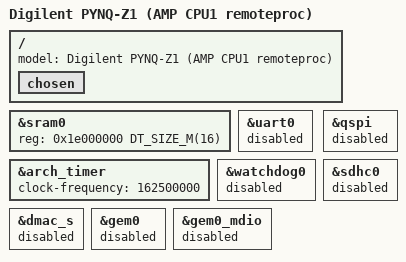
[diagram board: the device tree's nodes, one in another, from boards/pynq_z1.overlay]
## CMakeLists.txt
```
cmake_minimum_required(VERSION 3.20.0)

find_package(Zephyr REQUIRED HINTS $ENV{ZEPHYR_BASE})
project(pynq_z1_amp_cpu1)

target_sources(app PRIVATE src/main.c)
zephyr_linker_sources(SECTIONS resource_table.ld)
```

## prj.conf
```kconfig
# AMP CPU1 configuration: coexist with Linux on CPU0
CONFIG_USE_SWITCH=y
CONFIG_FPU=n
CONFIG_SMP=n
CONFIG_MP_MAX_NUM_CPUS=1
CONFIG_GIC_SAFE_CONFIG=y
CONFIG_NOCACHE_MEMORY=y
CONFIG_CACHE_MANAGEMENT=y

# OpenAMP / RPMsg (remote/device role paired with Linux zynq_remoteproc)
CONFIG_OPENAMP=y
CONFIG_OPENAMP_MASTER=n
CONFIG_OPENAMP_SLAVE=y
CONFIG_HEAP_MEM_POOL_SIZE=16384
CONFIG_MAIN_STACK_SIZE=4096

# Linux on CPU0 owns UART0 and Ethernet GEM0; log via remoteproc RSC_TRACE
CONFIG_SERIAL=n
CONFIG_CONSOLE=n
CONFIG_UART_CONSOLE=n
CONFIG_BOOT_BANNER=n
CONFIG_PRINTK=n
CONFIG_LOG=n
```

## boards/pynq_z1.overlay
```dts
/*
 * SPDX-License-Identifier: Apache-2.0
 *
 * Relocate Zephyr into the 16 MiB remoteproc carveout (0x1e000000) and disable
 * peripherals owned by Linux on CPU0 (UART0, GEM0).
 */

/ {
	model = "Digilent PYNQ-Z1 (AMP CPU1 remoteproc)";

	chosen {
		/delete-property/ zephyr,console;
		/delete-property/ zephyr,shell-uart;
	};
};

&sram0 {
	reg = <0x1e000000 DT_SIZE_M(16)>;
};

/* PYNQ Linux configures Cortex-A9 GTC_CTRL prescaler=1 (/2): 325 MHz / 2 = 162.5 MHz */
&arch_timer {
	clock-frequency = <162500000>;
};

&uart0 {
	status = "disabled";
};

&watchdog0 {
	status = "disabled";
};

&qspi {
	status = "disabled";
};

&sdhc0 {
	status = "disabled";
};

&dmac_s {
	status = "disabled";
};

&gem0 {
	status = "disabled";
};

&gem0_mdio {
	status = "disabled";
};
```

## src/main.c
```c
/*
 * SPDX-License-Identifier: Apache-2.0
 *
 * Zephyr AMP + OpenAMP/RPMsg firmware for Zynq-7000 CPU1 loaded by Linux
 * zynq_remoteproc.
 *  - Trace buffer: /sys/kernel/debug/remoteproc/remoteproc0/trace0
 *  - RPMsg echo endpoint: "rpmsg-raw" (/dev/rpmsg0 via Linux rpmsg_char)
 *  - Inter-processor kicks: GICv1 SGI #14 (Linux -> CPU1) and SGI #15 (CPU1 -> Linux)
 */

#include <zephyr/arch/cpu.h>
#include <zephyr/cache.h>
#include <zephyr/irq.h>
#include <zephyr/kernel.h>
#include <zephyr/linker/linker-defs.h>
#include <zephyr/linker/section_tags.h>
#include <zephyr/sys/barrier.h>
#include <zephyr/sys/sys_io.h>
#include <cmsis_core.h>
#include <openamp/open_amp.h>
#include <metal/io.h>
#include <metal/sys.h>
#include <stddef.h>
#include <stdint.h>
#include <stdio.h>
#include <stdlib.h>
#include <string.h>

#define AMP_TRACE_BUF_SIZE 2048U

/* Shared memory layout matching amp/openamp.dts */
#define SHM_REGION_ADDR 0x1F000000U
#define SHM_REGION_SIZE 0x00108000U
#define VRING0_ADDR     0x1F000000U
#define VRING1_ADDR     0x1F004000U
#define VRING_ALIGN     4096U
#define VRING_NUM       16U

/* Zynq-7000 GICv1 SGI registers (zynq_remoteproc uses SGIs 14 and 15) */
#define GICD_SGIR_ADDR   0xF8F01F00U
#define SGI_FROM_LINUX_0 14U
#define SGI_FROM_LINUX_1 15U
#define SGI_TO_LINUX     15U

/* PYNQ-Z1 base.bit AXI GPIO physical addresses (from base.hwh) */
#define AXI_SW_BASE      0x41200000U /* SW0-SW1 (2 bits) */
#define AXI_BTN_BASE     0x41210000U /* BTN0-BTN3 (4 bits) */
#define AXI_RGB_BASE     0x41240000U /* LD4-LD5 RGB (6 bits) */
#define AXI_LED_BASE     0x41250000U /* LD0-LD3 (4 bits) */
#define AXI_GPIO_DATA    0x00U
#define AXI_GPIO_TRI     0x04U

#define RPMSG_SVC_NAME "rpmsg-raw"

static char amp_trace_buf[AMP_TRACE_BUF_SIZE] __nocache;
static size_t amp_trace_pos;

void relocate_vector_table(void)
{
	uint32_t sctlr = __get_SCTLR();

	L1C_InvalidateICacheAll();
	L1C_InvalidateBTAC();
	L1C_InvalidateDCacheAll();
	/* Join Cortex-A9 SCU coherency (Linux already enabled SCU on CPU0) */
	__set_ACTLR(__get_ACTLR() | BIT(6) | BIT(0));

	sctlr &= ~SCTLR_V_Msk; /* Clear HIVECS so VBAR is active */
	__set_SCTLR(sctlr);
	__set_VBAR((uint32_t)_vector_start);
	barrier_dsync_fence_full();
	barrier_isync_fence_full();
}

struct amp_resource_table {
	uint32_t ver;
	uint32_t num;
	uint32_t reserved[2];
	uint32_t offset[2];
	struct fw_rsc_trace trace;
	struct fw_rsc_vdev rpmsg_vdev;
	struct fw_rsc_vdev_vring vring0;
	struct fw_rsc_vdev_vring vring1;
} __packed;

__attribute__((section(".resource_table"), used))
struct amp_resource_table rproc_resource_table = {
	.ver = 1U,
	.num = 2U,
	.reserved = { 0U, 0U },
	.offset = {
		offsetof(struct amp_resource_table, trace),
		offsetof(struct amp_resource_table, rpmsg_vdev),
	},
	.trace = {
		.type = RSC_TRACE,
		.da = (uint32_t)(uintptr_t)amp_trace_buf,
		.len = AMP_TRACE_BUF_SIZE,
		.reserved = 0U,
		.name = "zephyr_cpu1_trace",
	},
	.rpmsg_vdev = {
		.type = RSC_VDEV,
		.id = VIRTIO_ID_RPMSG,
		.notifyid = 0U,
		.dfeatures = (1U << VIRTIO_RPMSG_F_NS),
		.gfeatures = 0U,
		.config_len = 0U,
		.status = 0U,
		.num_of_vrings = 2U,
		.reserved = { 0U, 0U },
	},
	.vring0 = {
		.da = VRING0_ADDR,
		.align = VRING_ALIGN,
		.num = VRING_NUM,
		.notifyid = 0U,
		.reserved = 0U,
	},
	.vring1 = {
		.da = VRING1_ADDR,
		.align = VRING_ALIGN,
		.num = VRING_NUM,
		.notifyid = 1U,
		.reserved = 0U,
	},
};

static void trace_append(const char *msg)
{
	size_t len = strlen(msg);

	if (len >= AMP_TRACE_BUF_SIZE - 1U) {
		return;
	}

	if (amp_trace_pos + len >= AMP_TRACE_BUF_SIZE - 1U) {
		amp_trace_pos = 0U;
	}

	memcpy(&amp_trace_buf[amp_trace_pos], msg, len);
	amp_trace_pos += len;
	amp_trace_buf[amp_trace_pos] = '\0';
	barrier_dsync_fence_full();
}

static K_SEM_DEFINE(rpmsg_kick_sem, 0, 1);
static struct metal_io_region shm_io;
static struct metal_io_region rsc_io;
static metal_phys_addr_t shm_phys = SHM_REGION_ADDR;
static metal_phys_addr_t rsc_phys;
static struct rpmsg_virtio_device rvdev;
static struct rpmsg_endpoint raw_ept;
static uint32_t msg_count;
static uint32_t blink_period_ms;
static uint8_t blink_step;

static void axi_gpio_init_pl(void)
{
	/* Configure LD0-LD3 and RGB LD4-LD5 as outputs (TRI=0) */
	sys_write32(0x0U, AXI_LED_BASE + AXI_GPIO_TRI);
	sys_write32(0x0U, AXI_RGB_BASE + AXI_GPIO_TRI);
}

static void blink_timer_cb(struct k_timer *timer)
{
	static const uint8_t pattern[4] = { 0x1U, 0x2U, 0x4U, 0x8U };

	ARG_UNUSED(timer);
	sys_write32(pattern[blink_step & 0x3U], AXI_LED_BASE + AXI_GPIO_DATA);
	blink_step++;
}

static K_TIMER_DEFINE(pl_blink_timer, blink_timer_cb, NULL);

/* 1 kHz real-time jitter benchmark (325 MHz Cortex-A9 Global Timer) */
struct jitter_bench {
	struct k_sem done;
	uint32_t target_samples;
	uint32_t count;
	uint32_t prev_cyc;
	uint32_t min_cyc;
	uint32_t max_cyc;
	uint32_t max_err_cyc;
	uint64_t sum_cyc;
};

static struct jitter_bench jbench;

static void jitter_timer_cb(struct k_timer *timer)
{
	uint32_t now = k_cycle_get_32();

	if (jbench.count > 0U) {
		uint32_t dt = now - jbench.prev_cyc;
		uint32_t expected = CONFIG_SYS_CLOCK_HW_CYCLES_PER_SEC / 1000U;
		uint32_t err = (dt > expected) ? (dt - expected) : (expected - dt);

		if (dt < jbench.min_cyc) {
			jbench.min_cyc = dt;
		}
		if (dt > jbench.max_cyc) {
			jbench.max_cyc = dt;
		}
		if (err > jbench.max_err_cyc) {
			jbench.max_err_cyc = err;
		}
		jbench.sum_cyc += dt;
	}

	jbench.prev_cyc = now;
	jbench.count++;

	/* Toggle LD0 on every tick to prove live PL I/O inside the 1 kHz ISR */
	sys_write32(jbench.count & 0x1U, AXI_LED_BASE + AXI_GPIO_DATA);

	if (jbench.count > jbench.target_samples) {
		k_timer_stop(timer);
		k_sem_give(&jbench.done);
	}
}

static K_TIMER_DEFINE(jitter_timer, jitter_timer_cb, NULL);

/* Real-time 1 kHz failsafe supervisor (Linux heartbeat watchdog + PL BTN0 kill) */
enum ctrl_state {
	CTRL_DISARMED = 0,
	CTRL_ARMED = 1,
	CTRL_FAILSAFE = 2,
};

#define FAILSAFE_TIMEOUT_MS 500U
#define FAILSAFE_REBOOT_MS  5000U
#define SLCR_UNLOCK_REG     0xF8000008U
#define SLCR_PSS_RST_CTRL   0xF8000200U
#define RGB_BLUE_BOTH       0x09U /* LD4 blue (bit 0) + LD5 blue (bit 3) */
#define RGB_GREEN_BOTH      0x12U /* LD4 green (bit 1) + LD5 green (bit 4) */
#define RGB_RED_BOTH        0x24U /* LD4 red (bit 2) + LD5 red (bit 5) */

static volatile enum ctrl_state ctrl_mode = CTRL_DISARMED;
static volatile uint32_t last_cmd_ms;
static volatile uint32_t failsafe_enter_ms;
static volatile uint32_t ctrl_tick_count;
static volatile uint32_t failsafe_reason; /* 0=none, 1=timeout, 2=BTN0 kill */

static void zynq_ps_hardware_reset(void)
{
	/* Unlock Zynq-7000 SLCR and assert PSS_RST_CTRL (full PS reset) */
	sys_write32(0xDF0DU, SLCR_UNLOCK_REG);
	__DSB();
	sys_write32(0x1U, SLCR_PSS_RST_CTRL);
	__DSB();
	for (;;) {
		__WFE();
	}
}

static const char *ctrl_state_str(enum ctrl_state s)
{
	switch (s) {
	case CTRL_ARMED:
		return "ARMED";
	case CTRL_FAILSAFE:
		return "FAILSAFE";
	default:
		return "DISARMED";
	}
}

static void ctrl_timer_cb(struct k_timer *timer)
{
	ARG_UNUSED(timer);
	ctrl_tick_count++;

	if (ctrl_mode == CTRL_ARMED) {
		uint32_t btns = sys_read32(AXI_BTN_BASE + AXI_GPIO_DATA) & 0xFU;
		uint32_t now_ms = k_uptime_get_32();

		if ((btns & 0x1U) != 0U) {
			ctrl_mode = CTRL_FAILSAFE;
			failsafe_reason = 2U;
			sys_write32(0U, AXI_LED_BASE + AXI_GPIO_DATA);
			sys_write32(RGB_RED_BOTH, AXI_RGB_BASE + AXI_GPIO_DATA);
			trace_append("FAILSAFE: physical kill BTN0 triggered on CPU1\n");
		} else if ((now_ms - last_cmd_ms) > FAILSAFE_TIMEOUT_MS) {
			ctrl_mode = CTRL_FAILSAFE;
			failsafe_reason = 1U;
			failsafe_enter_ms = now_ms;
			sys_write32(0U, AXI_LED_BASE + AXI_GPIO_DATA);
			sys_write32(RGB_RED_BOTH, AXI_RGB_BASE + AXI_GPIO_DATA);
			trace_append("FAILSAFE: Linux command timeout (>500 ms) on CPU1\n");
		}
	} else if (ctrl_mode == CTRL_FAILSAFE) {
		/* Flash RGB LEDs red at 4 Hz while in failsafe */
		uint32_t red = ((ctrl_tick_count / 125U) & 0x1U) ? RGB_RED_BOTH : 0U;

		sys_write32(red, AXI_RGB_BASE + AXI_GPIO_DATA);

		/* If Linux stays dead for 5 s after timeout, hardware-reset PS */
		if (failsafe_reason == 1U &&
		    (k_uptime_get_32() - failsafe_enter_ms) >= FAILSAFE_REBOOT_MS) {
			trace_append("FAILSAFE: Linux dead 5s -> SLCR PSS_RST_CTRL reset\n");
			zynq_ps_hardware_reset();
		}
	}
}

static K_TIMER_DEFINE(ctrl_timer, ctrl_timer_cb, NULL);

static void sgi_kick_isr(const void *arg)
{
	ARG_UNUSED(arg);
	k_sem_give(&rpmsg_kick_sem);
}

static int zynq_amp_notify(void *priv, uint32_t id)
{
	ARG_UNUSED(priv);
	ARG_UNUSED(id);

	/* Raise GICv1 SGI #15 targeted to CPU0 (Linux) */
	barrier_dsync_fence_full();
	sys_write32((1U << 16) | SGI_TO_LINUX, GICD_SGIR_ADDR);
	barrier_dsync_fence_full();
	return 0;
}

static int raw_ept_cb(struct rpmsg_endpoint *ept, void *data, size_t len,
		      uint32_t src, void *priv)
{
	char rx_buf[128];
	char tx_buf[192];
	size_t copy_len = (len < sizeof(rx_buf) - 1U) ? len : (sizeof(rx_buf) - 1U);

	ARG_UNUSED(src);
	ARG_UNUSED(priv);

	memcpy(rx_buf, data, copy_len);
	rx_buf[copy_len] = '\0';
	while (copy_len > 0U && (rx_buf[copy_len - 1U] == '\n' || rx_buf[copy_len - 1U] == '\r')) {
		rx_buf[--copy_len] = '\0';
	}

	msg_count++;
	trace_append("RX: ");
	trace_append(rx_buf);
	trace_append("\n");

	if (strncmp(rx_buf, "led ", 4) == 0) {
		uint32_t val = (uint32_t)strtoul(&rx_buf[4], NULL, 0) & 0xFU;

		k_timer_stop(&pl_blink_timer);
		blink_period_ms = 0U;
		sys_write32(val, AXI_LED_BASE + AXI_GPIO_DATA);
		snprintf(tx_buf, sizeof(tx_buf), "OK led=0x%x\n", val);
	} else if (strncmp(rx_buf, "rgb ", 4) == 0) {
		uint32_t val = (uint32_t)strtoul(&rx_buf[4], NULL, 0) & 0x3FU;

		sys_write32(val, AXI_RGB_BASE + AXI_GPIO_DATA);
		snprintf(tx_buf, sizeof(tx_buf), "OK rgb=0x%02x\n", val);
	} else if (strncmp(rx_buf, "blink ", 6) == 0) {
		uint32_t ms = (uint32_t)strtoul(&rx_buf[6], NULL, 0);

		if (ms == 0U) {
			k_timer_stop(&pl_blink_timer);
			blink_period_ms = 0U;
			sys_write32(0U, AXI_LED_BASE + AXI_GPIO_DATA);
			snprintf(tx_buf, sizeof(tx_buf), "OK blink=stopped\n");
		} else {
			blink_period_ms = ms;
			k_timer_start(&pl_blink_timer, K_NO_WAIT, K_MSEC(ms));
			snprintf(tx_buf, sizeof(tx_buf), "OK blink=%u ms\n", ms);
		}
	} else if (strncmp(rx_buf, "jitter", 6) == 0) {
		uint32_t samples = (rx_buf[6] == ' ') ? (uint32_t)strtoul(&rx_buf[7], NULL, 0) : 1000U;

		if (samples < 10U || samples > 10000U) {
			samples = 1000U;
		}

		k_timer_stop(&pl_blink_timer);
		blink_period_ms = 0U;

		k_sem_init(&jbench.done, 0, 1);
		jbench.target_samples = samples;
		jbench.count = 0U;
		jbench.min_cyc = UINT32_MAX;
		jbench.max_cyc = 0U;
		jbench.max_err_cyc = 0U;
		jbench.sum_cyc = 0U;

		k_timer_start(&jitter_timer, K_MSEC(1), K_MSEC(1));
		k_sem_take(&jbench.done, K_MSEC(samples + 2000U));

		uint32_t min_ns = (uint32_t)(((uint64_t)jbench.min_cyc * 1000000000ULL) /
					     CONFIG_SYS_CLOCK_HW_CYCLES_PER_SEC);
		uint32_t max_ns = (uint32_t)(((uint64_t)jbench.max_cyc * 1000000000ULL) /
					     CONFIG_SYS_CLOCK_HW_CYCLES_PER_SEC);
		uint32_t avg_ns = (uint32_t)(((jbench.sum_cyc / samples) * 1000000000ULL) /
					     CONFIG_SYS_CLOCK_HW_CYCLES_PER_SEC);
		uint32_t jit_ns = (uint32_t)(((uint64_t)jbench.max_err_cyc * 1000000000ULL) /
					     CONFIG_SYS_CLOCK_HW_CYCLES_PER_SEC);

		snprintf(tx_buf, sizeof(tx_buf),
			 "OK n=%u min_us=%u.%03u max_us=%u.%03u avg_us=%u.%03u max_jitter_us=%u.%03u\n",
			 samples,
			 min_ns / 1000U, min_ns % 1000U,
			 max_ns / 1000U, max_ns % 1000U,
			 avg_ns / 1000U, avg_ns % 1000U,
			 jit_ns / 1000U, jit_ns % 1000U);
	} else if (strcmp(rx_buf, "arm") == 0) {
		k_timer_stop(&pl_blink_timer);
		blink_period_ms = 0U;
		last_cmd_ms = k_uptime_get_32();
		failsafe_reason = 0U;
		ctrl_mode = CTRL_ARMED;
		sys_write32(RGB_GREEN_BOTH, AXI_RGB_BASE + AXI_GPIO_DATA);
		k_timer_start(&ctrl_timer, K_MSEC(1), K_MSEC(1));
		snprintf(tx_buf, sizeof(tx_buf),
			 "OK state=ARMED timeout_ms=%u\n", FAILSAFE_TIMEOUT_MS);
	} else if (strcmp(rx_buf, "disarm") == 0) {
		k_timer_stop(&ctrl_timer);
		ctrl_mode = CTRL_DISARMED;
		failsafe_reason = 0U;
		sys_write32(0U, AXI_LED_BASE + AXI_GPIO_DATA);
		sys_write32(RGB_BLUE_BOTH, AXI_RGB_BASE + AXI_GPIO_DATA);
		snprintf(tx_buf, sizeof(tx_buf), "OK state=DISARMED\n");
	} else if (strncmp(rx_buf, "set ", 4) == 0) {
		uint32_t mask = (uint32_t)strtoul(&rx_buf[4], NULL, 0) & 0xFU;

		if (ctrl_mode == CTRL_ARMED) {
			uint32_t now_ms = k_uptime_get_32();
			uint32_t age_ms = now_ms - last_cmd_ms;

			last_cmd_ms = now_ms;
			sys_write32(mask, AXI_LED_BASE + AXI_GPIO_DATA);
			snprintf(tx_buf, sizeof(tx_buf),
				 "OK state=ARMED mask=0x%x age_ms=%u\n", mask, age_ms);
		} else {
			snprintf(tx_buf, sizeof(tx_buf),
				 "ERR state=%s reason=%u\n",
				 ctrl_state_str(ctrl_mode), failsafe_reason);
		}
	} else if (strcmp(rx_buf, "state") == 0) {
		snprintf(tx_buf, sizeof(tx_buf),
			 "OK state=%s reason=%u ticks=%u\n",
			 ctrl_state_str(ctrl_mode), failsafe_reason, ctrl_tick_count);
	} else if (strcmp(rx_buf, "read") == 0) {
		uint32_t btns = sys_read32(AXI_BTN_BASE + AXI_GPIO_DATA) & 0xFU;
		uint32_t sws = sys_read32(AXI_SW_BASE + AXI_GPIO_DATA) & 0x3U;
		uint32_t leds = sys_read32(AXI_LED_BASE + AXI_GPIO_DATA) & 0xFU;
		uint32_t rgb = sys_read32(AXI_RGB_BASE + AXI_GPIO_DATA) & 0x3FU;

		snprintf(tx_buf, sizeof(tx_buf),
			 "OK btns=0x%x sw=0x%x leds=0x%x rgb=0x%02x blink_ms=%u\n",
			 btns, sws, leds, rgb, blink_period_ms);
	} else {
		snprintf(tx_buf, sizeof(tx_buf), "[Zephyr CPU1 #%u] echo: %s\n", msg_count, rx_buf);
	}

	(void)rpmsg_send(ept, tx_buf, strlen(tx_buf));
	return RPMSG_SUCCESS;
}

static void ns_bind_cb(struct rpmsg_device *rdev, const char *name, uint32_t dest)
{
	ARG_UNUSED(rdev);
	ARG_UNUSED(name);
	ARG_UNUSED(dest);
}

int main(void)
{
	struct metal_init_params metal_params = METAL_INIT_DEFAULTS;
	struct virtio_device *vdev;
	struct rpmsg_device *rdev;
	char line[96];
	int ret;

	amp_trace_pos = 0U;
	axi_gpio_init_pl();
	trace_append("*** Zephyr AMP + OpenAMP + PL AXI GPIO on PYNQ-Z1 CPU1 booted ***\n");
	snprintf(line, sizeof(line), "MPIDR=0x%08x VBAR=0x%08x\n",
		 __get_MPIDR(), __get_VBAR());
	trace_append(line);

	IRQ_CONNECT(SGI_FROM_LINUX_0, 0, sgi_kick_isr, NULL, 0);
	IRQ_CONNECT(SGI_FROM_LINUX_1, 0, sgi_kick_isr, NULL, 0);
	irq_enable(SGI_FROM_LINUX_0);
	irq_enable(SGI_FROM_LINUX_1);

	ret = metal_init(&metal_params);
	if (ret != 0) {
		trace_append("ERROR: metal_init failed\n");
		return ret;
	}

	metal_io_init(&shm_io, (void *)SHM_REGION_ADDR, &shm_phys,
		      SHM_REGION_SIZE, -1, 0, NULL);

	rsc_phys = (metal_phys_addr_t)(uintptr_t)&rproc_resource_table;
	metal_io_init(&rsc_io, &rproc_resource_table, &rsc_phys,
		      sizeof(rproc_resource_table), -1, 0, NULL);

	sys_cache_data_invd_range(&rproc_resource_table, sizeof(rproc_resource_table));

	vdev = rproc_virtio_create_vdev(VIRTIO_DEV_DEVICE, 0U,
					&rproc_resource_table.rpmsg_vdev,
					&rsc_io, NULL, zynq_amp_notify, NULL);
	if (vdev == NULL) {
		trace_append("ERROR: rproc_virtio_create_vdev failed\n");
		return -1;
	}

	trace_append("Waiting for Linux remoteproc DRIVER_OK...\n");
	while ((rproc_resource_table.rpmsg_vdev.status & VIRTIO_CONFIG_STATUS_DRIVER_OK) == 0U) {
		sys_cache_data_invd_range(&rproc_resource_table, sizeof(rproc_resource_table));
		k_msleep(10);
	}
	trace_append("Linux DRIVER_OK received!\n");

	ret = rproc_virtio_init_vring(vdev, 0, rproc_resource_table.vring0.notifyid,
				      (void *)(uintptr_t)rproc_resource_table.vring0.da,
				      &shm_io, rproc_resource_table.vring0.num,
				      rproc_resource_table.vring0.align);
	if (ret != 0) {
		trace_append("ERROR: init_vring 0 failed\n");
		return ret;
	}

	ret = rproc_virtio_init_vring(vdev, 1, rproc_resource_table.vring1.notifyid,
				      (void *)(uintptr_t)rproc_resource_table.vring1.da,
				      &shm_io, rproc_resource_table.vring1.num,
				      rproc_resource_table.vring1.align);
	if (ret != 0) {
		trace_append("ERROR: init_vring 1 failed\n");
		return ret;
	}

	ret = rpmsg_init_vdev(&rvdev, vdev, ns_bind_cb, &shm_io, NULL);
	if (ret != 0) {
		trace_append("ERROR: rpmsg_init_vdev failed\n");
		return ret;
	}

	rdev = rpmsg_virtio_get_rpmsg_device(&rvdev);
	ret = rpmsg_create_ept(&raw_ept, rdev, RPMSG_SVC_NAME,
			       RPMSG_ADDR_ANY, RPMSG_ADDR_ANY,
			       raw_ept_cb, NULL);
	if (ret != 0) {
		trace_append("ERROR: rpmsg_create_ept failed\n");
		return ret;
	}

	trace_append("RPMsg endpoint 'rpmsg-raw' ready!\n");

	while (1) {
		k_sem_take(&rpmsg_kick_sem, K_MSEC(100));
		rproc_virtio_notified(rvdev.vdev, 0U);
		rproc_virtio_notified(rvdev.vdev, 1U);
	}

	return 0;
}
```
